# ATSAMA5D31 register map
Vendor: Atmel; Series: SAMA5D3; File version: 20130221
Registers are 32-bit, read-write, reset 0x0 unless marked. A register's access mark holds for its fields unless they carry their own. Offsets are from the block's base; [hi:lo] are bit positions; {n}, {i} and the like mark numbered series; 'fields as' and 'values as' point back to an identical list.

## LCDC — LCD Controller
Base 0xF0030000; register names take the prefix LCDC_
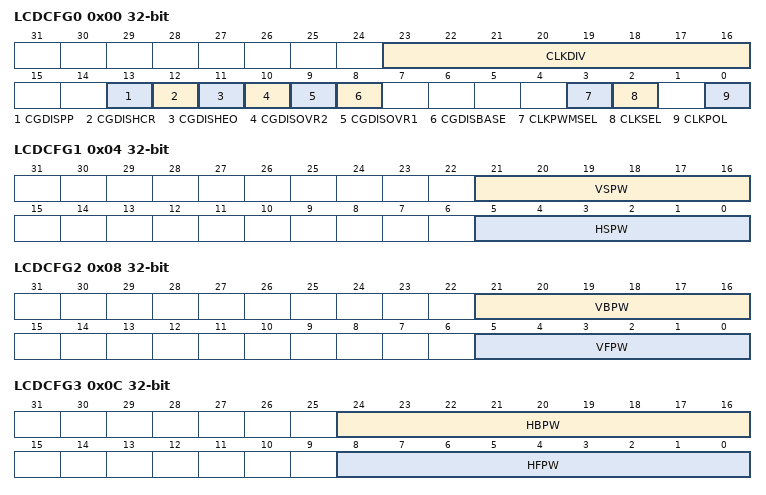
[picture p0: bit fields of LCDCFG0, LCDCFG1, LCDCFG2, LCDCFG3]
0x00 LCDCFG0 — LCD Controller Configuration Register 0
  [23:16] CLKDIV — LCD Controller Clock Divider
  [13] CGDISPP — Clock Gating Disable Control for the Post Processing Layer
  [12] CGDISHCR — Clock Gating Disable Control for the Hardware Cursor Layer
  [11] CGDISHEO — Clock Gating Disable Control for the High End Overlay
  [10] CGDISOVR2 — Clock Gating Disable Control for the Overlay 2 Layer
  [9] CGDISOVR1 — Clock Gating Disable Control for the Overlay 1 Layer
  [8] CGDISBASE — Clock Gating Disable Control for the Base Layer
  [3] CLKPWMSEL — LCD Controller PWM Clock Source Selection
  [2] CLKSEL — LCD Controller Clock Source Selection
  [0] CLKPOL — LCD Controller Clock Polarity
0x04 LCDCFG1 — LCD Controller Configuration Register 1
  [21:16] VSPW — Vertical Synchronization Pulse Width
  [5:0] HSPW — Horizontal Synchronization Pulse Width
0x08 LCDCFG2 — LCD Controller Configuration Register 2
  [21:16] VBPW — Vertical Back Porch Width
  [5:0] VFPW — Vertical Front Porch Width
0x0C LCDCFG3 — LCD Controller Configuration Register 3
  [24:16] HBPW — Horizontal Back Porch Width
  [8:0] HFPW — Horizontal Front Porch Width
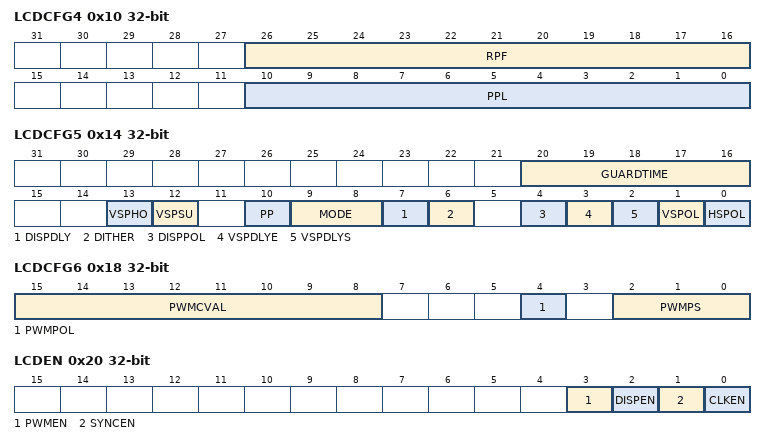
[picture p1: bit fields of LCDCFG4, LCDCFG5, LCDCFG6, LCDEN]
0x10 LCDCFG4 — LCD Controller Configuration Register 4
  [26:16] RPF — Number of Active Row Per Frame
  [10:0] PPL — Number of Pixels Per Line
0x14 LCDCFG5 — LCD Controller Configuration Register 5
  [20:16] GUARDTIME — LCD DISPLAY Guard Time
  [13] VSPHO — LCD Controller Vertical synchronization Pulse Hold Configuration
  [12] VSPSU — LCD Controller Vertical synchronization Pulse Setup Configuration
  [10] PP — Post Processing Enable
  [9:8] MODE — LCD Controller Output Mode
    0=OUTPUT_12BPP (LCD output mode is set to 12 bits per pixel); 1=OUTPUT_16BPP (LCD output mode is set to 16 bits per pixel); 2=OUTPUT_18BPP (LCD output mode is set to 18 bits per pixel); 3=OUTPUT_24BPP (LCD output mode is set to 24 bits per pixel)
  [7] DISPDLY — LCD Controller Display Power Signal Synchronization
  [6] DITHER — LCD Controller Dithering
  [4] DISPPOL — Display Signal Polarity
  [3] VSPDLYE — Vertical Synchronization Pulse End
  [2] VSPDLYS — Vertical Synchronization Pulse Start
  [1] VSPOL — Vertical Synchronization Pulse Polarity
  [0] HSPOL — Horizontal Synchronization Pulse Polarity
0x18 LCDCFG6 — LCD Controller Configuration Register 6
  [15:8] PWMCVAL — LCD Controller PWM Compare Value
  [4] PWMPOL — LCD Controller PWM Signal Polarity
  [2:0] PWMPS — PWM Clock Prescaler
0x20 LCDEN wo reset not defined — LCD Controller Enable Register
  [3] PWMEN — LCD Controller Pulse Width Modulation Enable
  [2] DISPEN — LCD Controller DISP Signal Enable
  [1] SYNCEN — LCD Controller Horizontal and Vertical Synchronization Enable
  [0] CLKEN — LCD Controller Pixel Clock Enable
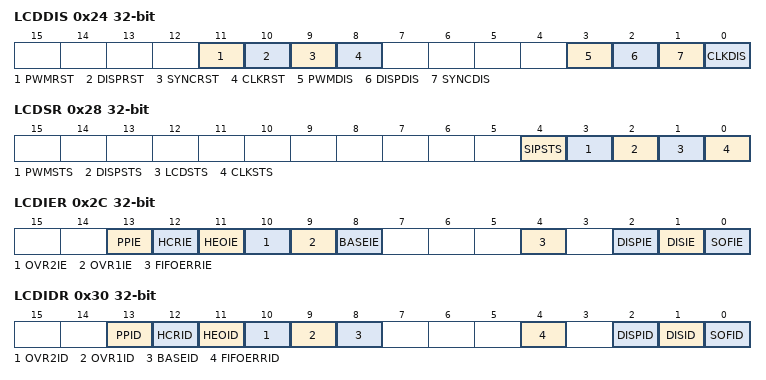
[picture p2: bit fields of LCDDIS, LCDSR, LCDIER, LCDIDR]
0x24 LCDDIS wo reset not defined — LCD Controller Disable Register
  [11] PWMRST — LCD Controller PWM Reset
  [10] DISPRST — LCD Controller DISP Signal Reset
  [9] SYNCRST — LCD Controller Horizontal and Vertical Synchronization Reset
  [8] CLKRST — LCD Controller Clock Reset
  [3] PWMDIS — LCD Controller Pulse Width Modulation Disable
  [2] DISPDIS — LCD Controller DISP Signal Disable
  [1] SYNCDIS — LCD Controller Horizontal and Vertical Synchronization Disable
  [0] CLKDIS — LCD Controller Pixel Clock Disable
0x28 LCDSR ro — LCD Controller Status Register
  [4] SIPSTS — Synchronization In Progress
  [3] PWMSTS — LCD Controller PWM Signal Status
  [2] DISPSTS — LCD Controller DISP Signal Status
  [1] LCDSTS — LCD Controller Synchronization status
  [0] CLKSTS — Clock Status
0x2C LCDIER wo reset not defined — LCD Controller Interrupt Enable Register
  [13] PPIE — Post Processing Interrupt Enable Register
  [12] HCRIE — Hardware Cursor Interrupt Enable Register
  [11] HEOIE — High End Overlay Interrupt Enable Register
  [10] OVR2IE — Overlay 2 Interrupt Enable Register
  [9] OVR1IE — Overlay 1 Interrupt Enable Register
  [8] BASEIE — Base Layer Interrupt Enable Register
  [4] FIFOERRIE — Output FIFO Error Interrupt Enable Register
  [2] DISPIE — Power UP/Down Sequence Terminated Interrupt Enable Register
  [1] DISIE — LCD Disable Interrupt Enable Register
  [0] SOFIE — Start of Frame Interrupt Enable Register
0x30 LCDIDR wo reset not defined — LCD Controller Interrupt Disable Register
  [13] PPID — Post Processing Interrupt Disable Register
  [12] HCRID — Hardware Cursor Interrupt Disable Register
  [11] HEOID — High End Overlay Interrupt Disable Register
  [10] OVR2ID — Overlay 2 Interrupt Disable Register
  [9] OVR1ID — Overlay 1 Interrupt Disable Register
  [8] BASEID — Base Layer Interrupt Disable Register
  [4] FIFOERRID — Output FIFO Error Interrupt Disable Register
  [2] DISPID — Power UP/Down Sequence Terminated Interrupt Disable Register
  [1] DISID — LCD Disable Interrupt Disable Register
  [0] SOFID — Start of Frame Interrupt Disable Register
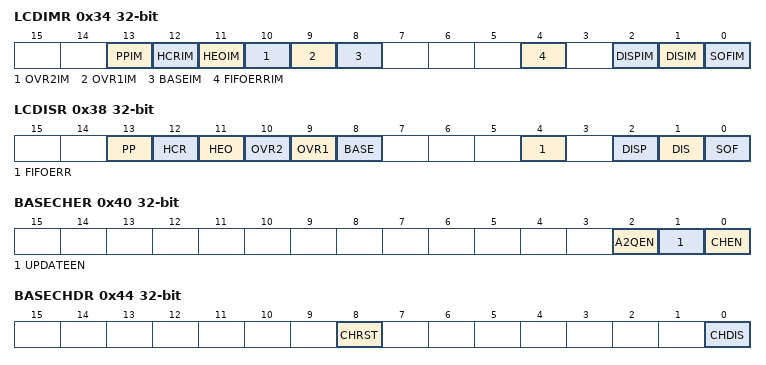
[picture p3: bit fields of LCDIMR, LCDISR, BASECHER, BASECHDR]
0x34 LCDIMR ro — LCD Controller Interrupt Mask Register
  [13] PPIM — Post Processing Interrupt Mask Register
  [12] HCRIM — Hardware Cursor Interrupt Mask Register
  [11] HEOIM — High End Overlay Interrupt Mask Register
  [10] OVR2IM — Overlay 2 Interrupt Mask Register
  [9] OVR1IM — Overlay 1 Interrupt Mask Register
  [8] BASEIM — Base Layer Interrupt Mask Register
  [4] FIFOERRIM — Output FIFO Error Interrupt Mask Register
  [2] DISPIM — Power UP/Down Sequence Terminated Interrupt Mask Register
  [1] DISIM — LCD Disable Interrupt Mask Register
  [0] SOFIM — Start of Frame Interrupt Mask Register
0x38 LCDISR ro — LCD Controller Interrupt Status Register
  [13] PP — Post Processing Raw Interrupt Status Register
  [12] HCR — Hardware Cursor Raw Interrupt Status Register
  [11] HEO — High End Overlay Raw Interrupt Status Register
  [10] OVR2 — Overlay 2 Raw Interrupt Status Register
  [9] OVR1 — Overlay 1 Raw Interrupt Status Register
  [8] BASE — Base Layer Raw Interrupt Status Register
  [4] FIFOERR — Output FIFO Error
  [2] DISP — Power-up/Power-down Sequence Terminated Interrupt Status Register
  [1] DIS — LCD Disable Interrupt Status Register
  [0] SOF — Start of Frame Interrupt Status Register
0x40 BASECHER wo — Base Layer Channel Enable Register
  [2] A2QEN — Add Head Pointer Enable Register
  [1] UPDATEEN — Update Overlay Attributes Enable Register
  [0] CHEN — Channel Enable Register
0x44 BASECHDR wo — Base Layer Channel Disable Register
  [8] CHRST — Channel Reset Register
  [0] CHDIS — Channel Disable Register
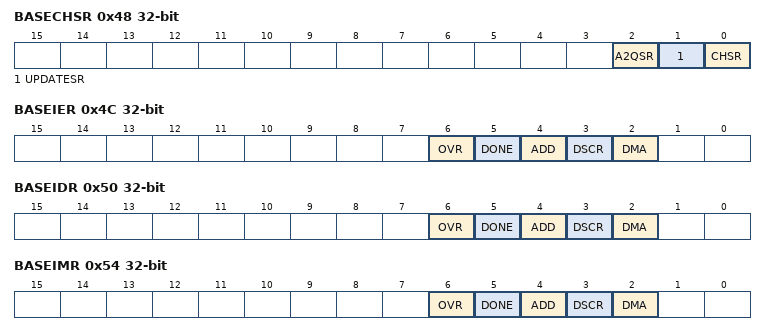
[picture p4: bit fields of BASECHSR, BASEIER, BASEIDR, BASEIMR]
0x48 BASECHSR ro — Base Layer Channel Status Register
  [2] A2QSR — Add To Queue Pending Register
  [1] UPDATESR — Update Overlay Attributes In Progress
  [0] CHSR — Channel Status Register
0x4C BASEIER wo — Base Layer Interrupt Enable Register
  [6] OVR — Overflow Interrupt Enable Register
  [5] DONE — End of List Interrupt Enable Register
  [4] ADD — Head Descriptor Loaded Interrupt Enable Register
  [3] DSCR — Descriptor Loaded Interrupt Enable Register
  [2] DMA — End of DMA Transfer Interrupt Enable Register
0x50 BASEIDR wo — Base Layer Interrupt Disabled Register
  [6] OVR — Overflow Interrupt Disable Register
  [5] DONE — End of List Interrupt Disable Register
  [4] ADD — Head Descriptor Loaded Interrupt Disable Register
  [3] DSCR — Descriptor Loaded Interrupt Disable Register
  [2] DMA — End of DMA Transfer Interrupt Disable Register
0x54 BASEIMR ro — Base Layer Interrupt Mask Register
  [6] OVR — Overflow Interrupt Mask Register
  [5] DONE — End of List Interrupt Mask Register
  [4] ADD — Head Descriptor Loaded Interrupt Mask Register
  [3] DSCR — Descriptor Loaded Interrupt Mask Register
  [2] DMA — End of DMA Transfer Interrupt Mask Register
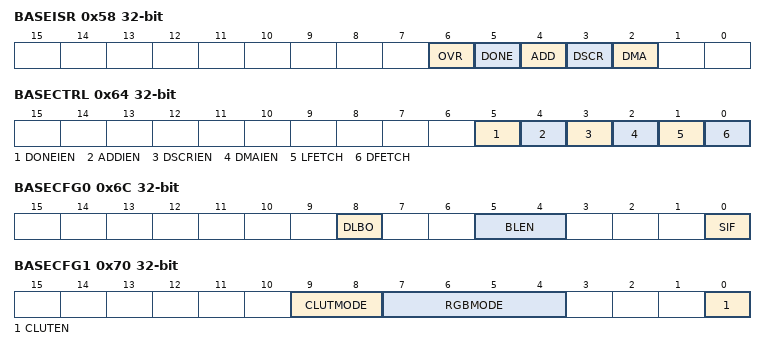
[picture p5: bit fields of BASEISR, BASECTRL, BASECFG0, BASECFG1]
0x58 BASEISR ro — Base Layer Interrupt status Register
  [6] OVR — Overflow Detected
  [5] DONE — End of List Detected
  [4] ADD — Head Descriptor Loaded
  [3] DSCR — DMA Descriptor Loaded
  [2] DMA — End of DMA Transfer
0x5C BASEHEAD — Base DMA Head Register
  [31:2] HEAD — DMA Head Pointer
0x60 BASEADDR — Base DMA Address Register
  [31:0] ADDR — DMA Transfer Start Address
0x64 BASECTRL — Base DMA Control Register
  [5] DONEIEN — End of List Interrupt Enable
  [4] ADDIEN — Add Head Descriptor to Queue Interrupt Enable
  [3] DSCRIEN — Descriptor Loaded Interrupt Enable
  [2] DMAIEN — End of DMA Transfer Interrupt Enable
  [1] LFETCH — Lookup Table Fetch Enable
  [0] DFETCH — Transfer Descriptor Fetch Enable
0x68 BASENEXT — Base DMA Next Register
  [31:0] NEXT — DMA Descriptor Next Address
0x6C BASECFG0 — Base Configuration register 0
  [8] DLBO — Defined Length Burst Only For Channel Bus Transaction.
  [5:4] BLEN — AHB Burst Length
    0=AHB_SINGLE (AHB Access is started as soon as there is enough space in the FIFO to store one data. SINGLE, INCR, INCR4, INCR8 and INCR16 bursts are used. INCR is used for a burst of 2 and 3 beats.); 1=AHB_INCR4 (AHB Access is started as soon as there is enough space in the FIFO to store a total amount of 4 data. An AHB INCR4 Burst is used. SINGLE, INCR and INCR4 bursts are used. INCR is used for a burst of 2 and 3 beats.); 2=AHB_INCR8 (AHB Access is started as soon as there is enough space in the FIFO to store a total amount of 8 data. An AHB INCR8 Burst is used. SINGLE, INCR, INCR4 and INCR8 bursts are used. INCR is used for a burst of 2 and 3 beats.); 3=AHB_INCR16 (AHB Access is started as soon as there is enough space in the FIFO to store a total amount of 16 data. An AHB INCR16 Burst is used. SINGLE, INCR, INCR4, INCR8 and INCR16 bursts are used. INCR is used for a burst of 2 and 3 beats.)
  [0] SIF — Source Interface
0x70 BASECFG1 — Base Configuration register 1
  [9:8] CLUTMODE — Color Lookup Table Input Mode Selection
    0=CLUT_1BPP (color lookup table mode set to 1 bit per pixel); 1=CLUT_2BPP (color lookup table mode set to 2 bits per pixel); 2=CLUT_4BPP (color lookup table mode set to 4 bits per pixel); 3=CLUT_8BPP (color lookup table mode set to 8 bits per pixel)
  [7:4] RGBMODE — RGB Input Mode Selection
    0=12BPP_RGB_444; 1=16BPP_ARGB_4444; 2=16BPP_RGBA_4444; 3=16BPP_RGB_565; 4=16BPP_TRGB_1555; 5=18BPP_RGB_666; 6=18BPP_RGB_666PACKED; 7=19BPP_TRGB_1666; 8=19BPP_TRGB_PACKED (19 bpp TRGB 1666 PACKED); 9=24BPP_RGB_888; 10=24BPP_RGB_888_PACKED; 11=25BPP_TRGB_1888; 12=32BPP_ARGB_8888; 13=32BPP_RGBA_8888
  [0] CLUTEN — Color Lookup Table Enable
0x74 BASECFG2 — Base Configuration register 2
  [31:0] XSTRIDE — Horizontal Stride
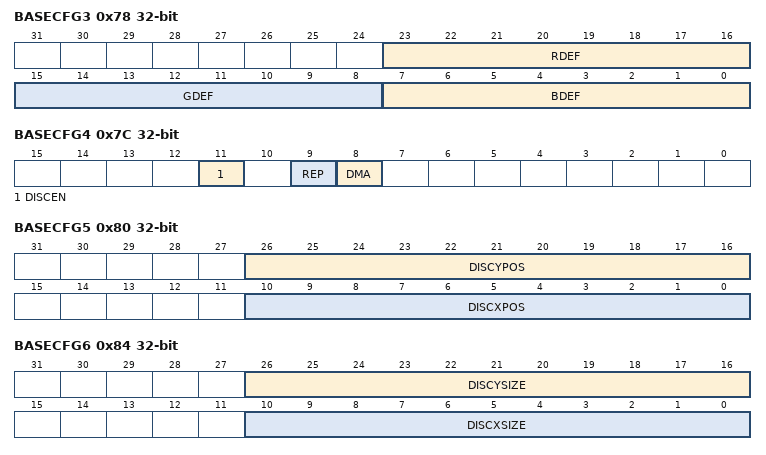
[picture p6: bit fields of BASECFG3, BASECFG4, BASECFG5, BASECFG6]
0x78 BASECFG3 — Base Configuration register 3
  [23:16] RDEF — Red Default
  [15:8] GDEF — Green Default
  [7:0] BDEF — Blue Default
0x7C BASECFG4 — Base Configuration register 4
  [11] DISCEN — Discard Area Enable
  [9] REP — Use Replication logic to expand RGB color to 24 bits
  [8] DMA — Use DMA Data Path
0x80 BASECFG5 — Base Configuration register 5
  [26:16] DISCYPOS — Discard Area Vertical coordinate
  [10:0] DISCXPOS — Discard Area horizontal coordinate
0x84 BASECFG6 — Base Configuration register 6
  [26:16] DISCYSIZE — Discard Area Vertical Size
  [10:0] DISCXSIZE — Discard Area Horizontal Size
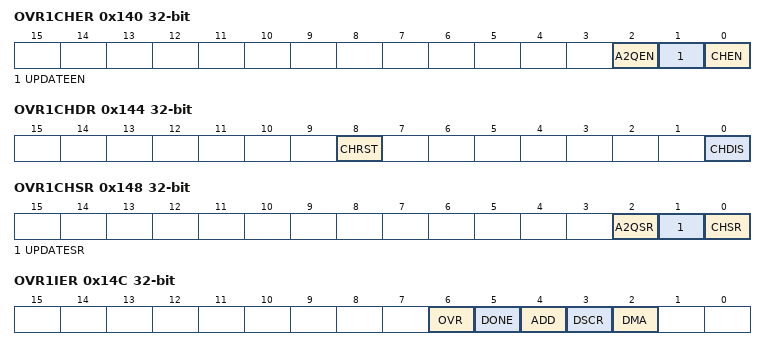
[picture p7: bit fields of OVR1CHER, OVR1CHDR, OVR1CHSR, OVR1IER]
0x140 OVR1CHER wo — Overlay 1 Channel Enable Register
  fields as BASECHER
0x144 OVR1CHDR wo — Overlay 1 Channel Disable Register
  fields as BASECHDR
0x148 OVR1CHSR ro — Overlay 1 Channel Status Register
  [2] A2QSR — Add to Queue Pending Register
  [1] UPDATESR — Update Overlay Attributes In Progress
  [0] CHSR — Channel Status Register
0x14C OVR1IER wo — Overlay 1 Interrupt Enable Register
  fields as BASEIER
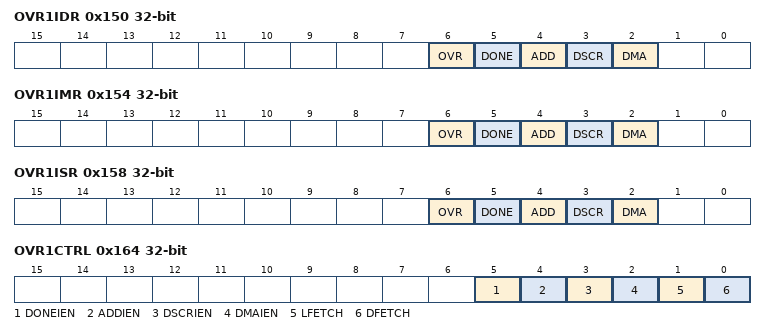
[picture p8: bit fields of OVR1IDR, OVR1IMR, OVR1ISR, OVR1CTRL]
0x150 OVR1IDR wo — Overlay 1 Interrupt Disable Register
  fields as BASEIDR
0x154 OVR1IMR ro — Overlay 1 Interrupt Mask Register
  fields as BASEIMR
0x158 OVR1ISR ro — Overlay 1 Interrupt Status Register
  [6] OVR — Overflow Detected
  [5] DONE — End of List Detected Register
  [4] ADD — Head Descriptor Loaded
  [3] DSCR — DMA Descriptor Loaded
  [2] DMA — End of DMA Transfer
0x15C OVR1HEAD — Overlay 1 DMA Head Register
  [31:2] HEAD — DMA Head Pointer
0x160 OVR1ADDR — Overlay 1 DMA Address Register
  [31:0] ADDR — DMA Transfer Overlay 1 Address
0x164 OVR1CTRL — Overlay1 DMA Control Register
  fields as BASECTRL
0x168 OVR1NEXT — Overlay1 DMA Next Register
  [31:0] NEXT — DMA Descriptor Next Address
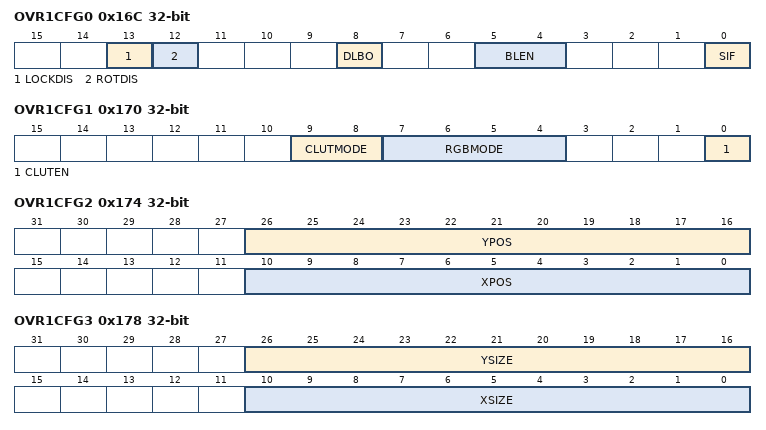
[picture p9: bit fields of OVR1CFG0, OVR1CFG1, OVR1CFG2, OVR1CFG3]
0x16C OVR1CFG0 — Overlay 1 Configuration 0 Register
  [13] LOCKDIS — Hardware Rotation Lock Disable
  [12] ROTDIS — Hardware Rotation Optimization Disable
  [8] DLBO — Defined Length Burst Only for Channel Bus Transaction.
  [5:4] BLEN — AHB Burst Length
    0=AHB_BLEN_SINGLE (AHB Access is started as soon as there is enough space in the FIFO to store one data. SINGLE, INCR, INCR4, INCR8 and INCR16 bursts are used. INCR is used for a burst of 2 and 3 beats.); 1=AHB_BLEN_INCR4 (AHB Access is started as soon as there is enough space in the FIFO to store a total amount of 4 data. An AHB INCR4 Burst is used. SINGLE, INCR and INCR4 bursts are used. INCR is used for a burst of 2 and 3 beats.); 2=AHB_BLEN_INCR8 (AHB Access is started as soon as there is enough space in the FIFO to store a total amount of 8 data. An AHB INCR8 Burst is used. SINGLE, INCR, INCR4 and INCR8 bursts are used. INCR is used for a burst of 2 and 3 beats.); 3=AHB_BLEN_INCR16 (AHB Access is started as soon as there is enough space in the FIFO to store a total amount of 16 data. An AHB INCR16 Burst is used. SINGLE, INCR, INCR4, INCR8 and INCR16 bursts are used. INCR is used for a burst of 2 and 3 beats.)
  [0] SIF — Source Interface
0x170 OVR1CFG1 — Overlay 1 Configuration 1 Register
  [9:8] CLUTMODE — Color Lookup table input mode selection
    values as BASECFG1.CLUTMODE
  [7:4] RGBMODE — RGB Input Mode Selection
    values as BASECFG1.RGBMODE
  [0] CLUTEN — Color Lookup Table Enable
0x174 OVR1CFG2 — Overlay 1 Configuration 2 Register
  [26:16] YPOS — Vertical Window Position
  [10:0] XPOS — Horizontal Window Position
0x178 OVR1CFG3 — Overlay 1 Configuration 3 Register
  [26:16] YSIZE — Vertical Window Size
  [10:0] XSIZE — Horizontal Window Size
0x17C OVR1CFG4 — Overlay 1 Configuration 4 Register
  [31:0] XSTRIDE — Horizontal Stride
0x180 OVR1CFG5 — Overlay 1 Configuration 5 Register
  [31:0] PSTRIDE — Pixel Stride
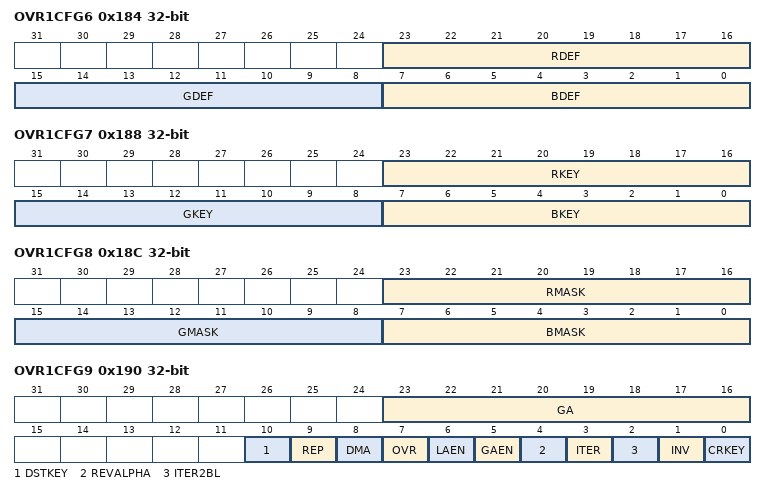
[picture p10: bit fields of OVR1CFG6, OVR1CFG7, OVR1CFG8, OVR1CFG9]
0x184 OVR1CFG6 — Overlay 1 Configuration 6 Register
  fields as BASECFG3
0x188 OVR1CFG7 — Overlay 1 Configuration 7 Register
  [23:16] RKEY — Red Color Component Chroma Key
  [15:8] GKEY — Green Color Component Chroma Key
  [7:0] BKEY — Blue Color Component Chroma Key
0x18C OVR1CFG8 — Overlay 1 Configuration 8Register
  [23:16] RMASK — Red Color Component Chroma Key Mask
  [15:8] GMASK — Green Color Component Chroma Key Mask
  [7:0] BMASK — Blue Color Component Chroma Key Mask
0x190 OVR1CFG9 — Overlay 1 Configuration 9 Register
  [23:16] GA — Blender Global Alpha
  [10] DSTKEY — Destination Chroma Keying
  [9] REP — Use Replication logic to expand RGB color to 24 bits
  [8] DMA — Blender DMA Layer Enable
  [7] OVR — Blender Overlay Layer Enable
  [6] LAEN — Blender Local Alpha Enable
  [5] GAEN — Blender Global Alpha Enable
  [4] REVALPHA — Blender Reverse Alpha
  [3] ITER — Blender Use Iterated Color
  [2] ITER2BL — Blender Iterated Color Enable
  [1] INV — Blender Inverted Blender Output Enable
  [0] CRKEY — Blender Chroma Key Enable
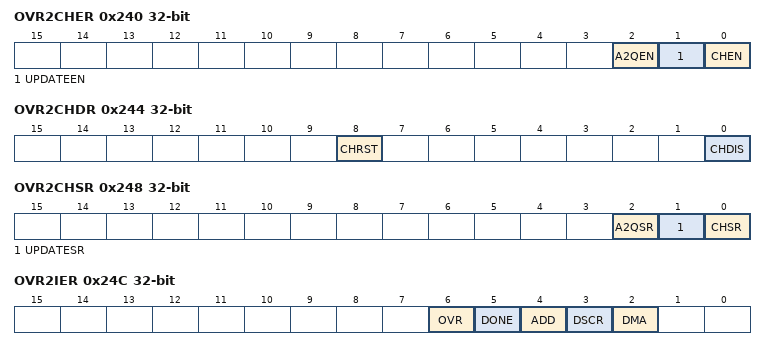
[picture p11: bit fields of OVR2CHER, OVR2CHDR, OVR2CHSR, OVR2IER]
0x240 OVR2CHER wo — Overlay 2 Channel Enable Register
  fields as BASECHER
0x244 OVR2CHDR wo — Overlay 2 Channel Disable Register
  fields as BASECHDR
0x248 OVR2CHSR ro — Overlay 2 Channel Status Register
  fields as BASECHSR
0x24C OVR2IER wo — Overlay 2 Interrupt Enable Register
  fields as BASEIER
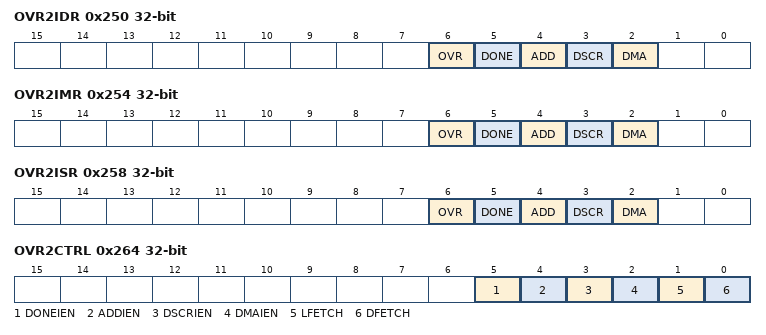
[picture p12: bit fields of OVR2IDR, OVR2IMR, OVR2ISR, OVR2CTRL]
0x250 OVR2IDR wo — Overlay 2 Interrupt Disable Register
  fields as BASEIDR
0x254 OVR2IMR ro — Overlay 2 Interrupt Mask Register
  fields as BASEIMR
0x258 OVR2ISR ro — Overlay 2 Interrupt status Register
  [6] OVR — Overflow Detected
  [5] DONE — End Of List Interrupt Disable Register
  [4] ADD — Head Descriptor Loaded Interrupt Disable Register
  [3] DSCR — DMA Descriptor Loaded
  [2] DMA — End of DMA Transfer
0x25C OVR2HEAD — Overlay 2 DMA Head Register
  [31:2] HEAD — DMA Head Pointer
0x260 OVR2ADDR — Overlay 2 DMA Address Register
  [31:0] ADDR — DMA Transfer Overlay 2 Address
0x264 OVR2CTRL — Overlay 2 DMA Control Register
  fields as BASECTRL
0x268 OVR2NEXT — Overlay 2 DMA Next Register
  [31:0] NEXT — DMA Descriptor Next Address
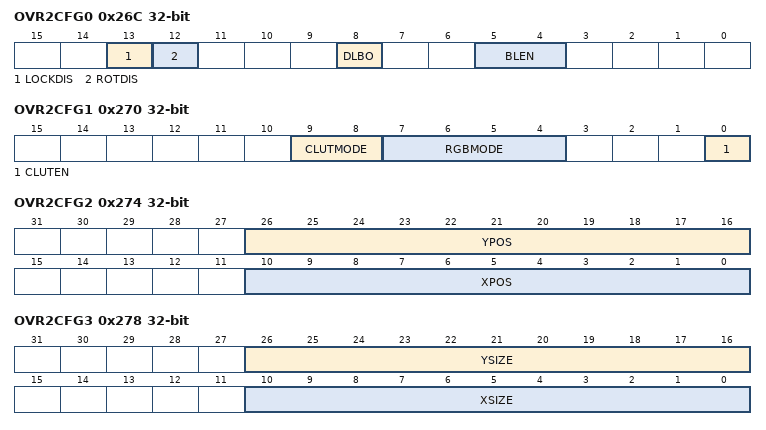
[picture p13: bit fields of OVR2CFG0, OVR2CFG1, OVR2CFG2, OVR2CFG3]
0x26C OVR2CFG0 — Overlay 2 Configuration 0 Register
  [13] LOCKDIS — Hardware Rotation Lock Disable
  [12] ROTDIS — Hardware Rotation Optimization Disable
  [8] DLBO — Defined Length Burst Only For Channel Bus Transaction.
  [5:4] BLEN — AHB Burst Length
    values as BASECFG0.BLEN
0x270 OVR2CFG1 — Overlay 2 Configuration 1 Register
  fields as OVR1CFG1
0x274 OVR2CFG2 — Overlay 2 Configuration 2 Register
  fields as OVR1CFG2
0x278 OVR2CFG3 — Overlay 2 Configuration 3 Register
  fields as OVR1CFG3
0x27C OVR2CFG4 — Overlay 2 Configuration 4 Register
  [31:0] XSTRIDE — Horizontal Stride
0x280 OVR2CFG5 — Overlay 2 Configuration 5 Register
  [31:0] PSTRIDE — Pixel Stride
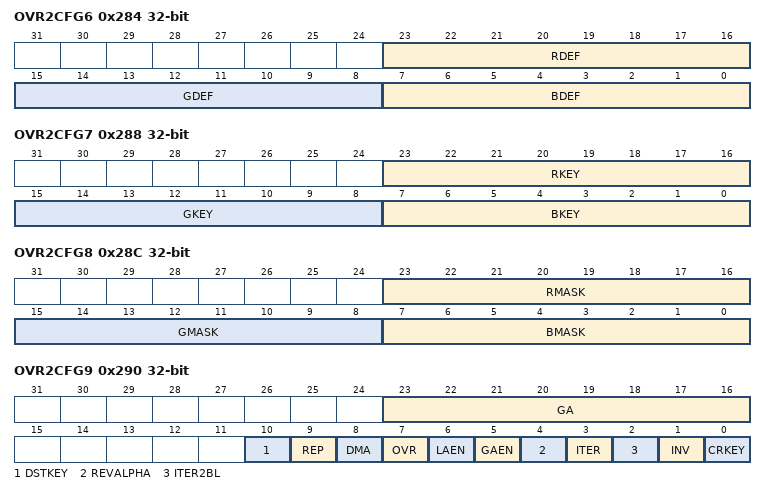
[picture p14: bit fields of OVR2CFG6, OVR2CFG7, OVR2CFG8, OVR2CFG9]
0x284 OVR2CFG6 — Overlay 2 Configuration 6 Register
  fields as BASECFG3
0x288 OVR2CFG7 — Overlay 2 Configuration 7 Register
  fields as OVR1CFG7
0x28C OVR2CFG8 — Overlay 2 Configuration 8 Register
  fields as OVR1CFG8
0x290 OVR2CFG9 — Overlay 2 Configuration 9 Register
  fields as OVR1CFG9
0x340 HEOCHER wo — High-End Overlay Channel Enable Register
  fields as BASECHER
0x344 HEOCHDR wo — High-End Overlay Channel Disable Register
  fields as BASECHDR
0x348 HEOCHSR ro — High-End Overlay Channel Status Register
  fields as BASECHSR
0x34C HEOIER wo — High-End Overlay Interrupt Enable Register
  [22] VOVR — Overflow for V Chrominance Interrupt Enable Register
  [21] VDONE — End of List for V Chrominance Interrupt Enable Register
  [20] VADD — Head Descriptor Loaded for V Chrominance Interrupt Enable Register
  [19] VDSCR — Descriptor Loaded for V Chrominance Interrupt Enable Register
  [18] VDMA — End of DMA for V Chrominance Transfer Interrupt Enable Register
  [14] UOVR — Overflow for U or UV Chrominance Interrupt Enable Register
  [13] UDONE — End of List for U or UV Chrominance Interrupt Enable Register
  [12] UADD — Head Descriptor Loaded for U or UV Chrominance Interrupt Enable Register
  [11] UDSCR — Descriptor Loaded for U or UV Chrominance Interrupt Enable Register
  [10] UDMA — End of DMA Transfer for U or UV Chrominance Interrupt Enable Register
  [6] OVR — Overflow Interrupt Enable Register
  [5] DONE — End of List Interrupt Enable Register
  [4] ADD — Head Descriptor Loaded Interrupt Enable Register
  [3] DSCR — Descriptor Loaded Interrupt Enable Register
  [2] DMA — End of DMA Transfer Interrupt Enable Register
0x350 HEOIDR wo — High-End Overlay Interrupt Disable Register
  [22] VOVR — Overflow for V Chrominance Component Interrupt Disable Register
  [21] VDONE — End of List for V Chrominance Component Interrupt Disable Register
  [20] VADD — Head Descriptor Loaded for V Chrominance Component Interrupt Disable Register
  [19] VDSCR — Descriptor Loaded for V Chrominance Component Interrupt Disable Register
  [18] VDMA — End of DMA Transfer for V Chrominance Component Interrupt Disable Register
  [14] UOVR — Overflow Interrupt for U or UV Chrominance Component Disable Register
  [13] UDONE — End of List Interrupt for U or UV Chrominance Component Disable Register
  [12] UADD — Head Descriptor Loaded for U or UV Chrominance Component Interrupt Disable Register
  [11] UDSCR — Descriptor Loaded for U or UV Chrominance Component Interrupt Disable Register
  [10] UDMA — End of DMA Transfer for U or UV Chrominance Component Interrupt Disable Register
  [6] OVR — Overflow Interrupt Disable Register
  [5] DONE — End of List Interrupt Disable Register
  [4] ADD — Head Descriptor Loaded Interrupt Disable Register
  [3] DSCR — Descriptor Loaded Interrupt Disable Register
  [2] DMA — End of DMA Transfer Interrupt Disable Register
0x354 HEOIMR ro — High-End Overlay Interrupt Mask Register
  [22] VOVR — Overflow for V Chrominance Interrupt Mask Register
  [21] VDONE — End of List for V Chrominance Component Mask Register
  [20] VADD — Head Descriptor Loaded for V Chrominance Component Mask Register
  [19] VDSCR — Descriptor Loaded for V Chrominance Component Interrupt Mask Register
  [18] VDMA — End of DMA Transfer for V Chrominance Component Interrupt Mask Register
  [14] UOVR — Overflow for U Chrominance Interrupt Mask Register
  [13] UDONE — End of List for U or UV Chrominance Component Mask Register
  [12] UADD — Head Descriptor Loaded for U or UV Chrominance Component Mask Register
  [11] UDSCR — Descriptor Loaded for U or UV Chrominance Component Interrupt Mask Register
  [10] UDMA — End of DMA Transfer for U or UV Chrominance Component Interrupt Mask Register
  [6] OVR — Overflow Interrupt Mask Register
  [5] DONE — End of List Interrupt Mask Register
  [4] ADD — Head Descriptor Loaded Interrupt Mask Register
  [3] DSCR — Descriptor Loaded Interrupt Mask Register
  [2] DMA — End of DMA Transfer Interrupt Mask Register
0x358 HEOISR ro — High-End Overlay Interrupt Status Register
  [22] VOVR — Overflow Detected for V component
  [21] VDONE — End of List Detected for V component
  [20] VADD — Head Descriptor Loaded for V component
  [19] VDSCR — DMA Descriptor Loaded for V component
  [18] VDMA — End of DMA Transfer for V component
  [14] UOVR — Overflow Detected for U component
  [13] UDONE — End of List Detected for U component
  [12] UADD — Head Descriptor Loaded for U component
  [11] UDSCR — DMA Descriptor Loaded for U component
  [10] UDMA — End of DMA Transfer for U component
  [6] OVR — Overflow Detected
  [5] DONE — End of List Detected
  [4] ADD — Head Descriptor Loaded
  [3] DSCR — DMA Descriptor Loaded
  [2] DMA — End of DMA Transfer
0x35C HEOHEAD — High-End Overlay DMA Head Register
  [31:2] HEAD — DMA Head Pointer
0x360 HEOADDR — High-End Overlay DMA Address Register
  [31:0] ADDR — DMA Transfer start Address
0x364 HEOCTRL — High-End Overlay DMA Control Register
  fields as BASECTRL
0x368 HEONEXT — High-End Overlay DMA Next Register
  [31:0] NEXT — DMA Descriptor Next Address
0x36C HEOUHEAD — High-End Overlay U DMA Head Register
  [31:0] UHEAD — DMA Head Pointer
0x370 HEOUADDR — High-End Overlay U DMA Address Register
  [31:0] UADDR — DMA Transfer Start Address for U or UV Chrominance
0x374 HEOUCTRL — High-End Overlay U DMA control Register
  [5] UDONEIEN — End of List Interrupt Enable
  [4] UADDIEN — Add Head Descriptor to Queue Interrupt Enable
  [3] UDSCRIEN — Descriptor Loaded Interrupt Enable
  [2] UDMAIEN — End of DMA Transfer Interrupt Enable
  [0] UDFETCH — Transfer Descriptor Fetch Enable
0x378 HEOUNEXT — High-End Overlay U DMA Next Register
  [31:0] UNEXT — DMA Descriptor Next Address
0x37C HEOVHEAD — High-End Overlay V DMA Head Register
  [31:0] VHEAD — DMA Head Pointer
0x380 HEOVADDR — High-End Overlay V DMA Address Register
  [31:0] VADDR — DMA Transfer Start Address for V Chrominance
0x384 HEOVCTRL — High-End Overlay V DMA control Register
  [5] VDONEIEN — End of List Interrupt Enable
  [4] VADDIEN — Add Head Descriptor to Queue Interrupt Enable
  [3] VDSCRIEN — Descriptor Loaded Interrupt Enable
  [2] VDMAIEN — End of DMA Transfer Interrupt Enable
  [0] VDFETCH — Transfer Descriptor Fetch Enable
0x388 HEOVNEXT — High-End Overlay VDMA Next Register
  [31:0] VNEXT — DMA Descriptor Next Address
0x38C HEOCFG0 — High-End Overlay Configuration Register 0
  [13] LOCKDIS — Hardware Rotation Lock Disable
  [12] ROTDIS — Hardware Rotation Optimization Disable
  [8] DLBO — Defined Length Burst Only For Channel Bus Transaction.
  [7:6] BLENUV — AHB Burst Length for U-V channel
    values as BASECFG0.BLEN
  [5:4] BLEN — AHB Burst Length
    values as OVR1CFG0.BLEN
  [0] SIF — Source Interface
0x390 HEOCFG1 — High-End Overlay Configuration Register 1
  [20] DSCALEOPT — Down Scaling Bandwidth Optimization
  [17] YUV422SWP — YUV 4:2:2 SWAP
  [16] YUV422ROT — YUV 4:2:2 Rotation
  [15:12] YUVMODE — YUV input mode selection
    0=32BPP_AYCBCR (32 bpp AYCbCr 444); 1=16BPP_YCBCR_MODE0 (16 bpp Cr(n)Y(n+1)Cb(n)Y(n) 422); 2=16BPP_YCBCR_MODE1 (16 bpp Y(n+1)Cr(n)Y(n)Cb(n) 422); 3=16BPP_YCBCR_MODE2 (16 bpp Cb(n)Y(+1)Cr(n)Y(n) 422); 4=16BPP_YCBCR_MODE3 (16 bpp Y(n+1)Cb(n)Y(n)Cr(n) 422); 5=16BPP_YCBCR_SEMIPLANAR (16 bpp Semiplanar 422 YCbCr); 6=16BPP_YCBCR_PLANAR (16 bpp Planar 422 YCbCr); 7=12BPP_YCBCR_SEMIPLANAR (12 bpp Semiplanar 420 YCbCr); 8=12BPP_YCBCR_PLANAR (12 bpp Planar 420 YCbCr)
  [9:8] CLUTMODE — Color Lookup table input mode selection
    values as BASECFG1.CLUTMODE
  [7:4] RGBMODE — RGB input mode selection
    values as BASECFG1.RGBMODE
  [1] YUVEN — YUV Color Space Enable
  [0] CLUTEN — Color Lookup Table Enable
0x394 HEOCFG2 — High-End Overlay Configuration Register 2
  fields as OVR1CFG2
0x398 HEOCFG3 — High-End Overlay Configuration Register 3
  fields as OVR1CFG3
0x39C HEOCFG4 — High-End Overlay Configuration Register 4
  [26:16] YMEMSIZE — Vertical image Size in Memory
  [10:0] XMEMSIZE — Horizontal image Size in Memory
0x3A0 HEOCFG5 — High-End Overlay Configuration Register 5
  [31:0] XSTRIDE — Horizontal Stride
0x3A4 HEOCFG6 — High-End Overlay Configuration Register 6
  [31:0] PSTRIDE — Pixel Stride
0x3A8 HEOCFG7 — High-End Overlay Configuration Register 7
  [31:0] UVXSTRIDE — UV Horizontal Stride
0x3AC HEOCFG8 — High-End Overlay Configuration Register 8
  [31:0] UVPSTRIDE — UV Pixel Stride
0x3B0 HEOCFG9 — High-End Overlay Configuration Register 9
  fields as BASECFG3
0x3B4 HEOCFG10 — High-End Overlay Configuration Register 10
  fields as OVR1CFG7
0x3B8 HEOCFG11 — High-End Overlay Configuration Register 11
  fields as OVR1CFG8
0x3BC HEOCFG12 — High-End Overlay Configuration Register 12
  [23:16] GA — Blender Global Alpha
  [12] VIDPRI — Video Priority
  [10] DSTKEY — Destination Chroma Keying
  [9] REP — Use Replication logic to expand RGB color to 24 bits
  [8] DMA — Blender DMA Layer Enable
  [7] OVR — Blender Overlay Layer Enable
  [6] LAEN — Blender Local Alpha Enable
  [5] GAEN — Blender Global Alpha Enable
  [4] REVALPHA — Blender Reverse Alpha
  [3] ITER — Blender Use Iterated Color
  [2] ITER2BL — Blender Iterated Color Enable
  [1] INV — Blender Inverted Blender Output Enable
  [0] CRKEY — Blender Chroma Key Enable
0x3C0 HEOCFG13 — High-End Overlay Configuration Register 13
  [31] SCALEN — Hardware Scaler Enable
  [29:16] YFACTOR — Vertical Scaling Factor
  [13:0] XFACTOR — Horizontal Scaling Factor
0x3C4 HEOCFG14 — High-End Overlay Configuration Register 14
  [30] CSCYOFF — Color Space Conversion Offset
  [29:20] CSCRV — Color Space Conversion V coefficient for Red Component 1:2:7 format
  [19:10] CSCRU — Color Space Conversion U coefficient for Red Component 1:2:7 format
  [9:0] CSCRY — Color Space Conversion Y coefficient for Red Component 1:2:7 format
0x3C8 HEOCFG15 — High-End Overlay Configuration Register 15
  [30] CSCUOFF — Color Space Conversion Offset
  [29:20] CSCGV — Color Space Conversion V coefficient for Green Component 1:2:7 format
  [19:10] CSCGU — Color Space Conversion U coefficient for Green Component 1:2:7 format
  [9:0] CSCGY — Color Space Conversion Y coefficient for Green Component 1:2:7 format
0x3CC HEOCFG16 — High-End Overlay Configuration Register 16
  [30] CSCVOFF — Color Space Conversion Offset
  [29:20] CSCBV — Color Space Conversion V coefficient for Blue Component 1:2:7 format
  [19:10] CSCBU — Color Space Conversion U coefficient for Blue Component 1:2:7 format
  [9:0] CSCBY — Color Space Conversion Y coefficient for Blue Component 1:2:7 format
0x3D0 HEOCFG17 — High-End Overlay Configuration Register 17
  [8n+7:8n] XPHI0COEFF{n} (n=0..3) — Horizontal Coefficient for phase 0 tap {n}
0x3D4 HEOCFG18 — High-End Overlay Configuration Register 18
  [7:0] XPHI0COEFF4 — Horizontal Coefficient for phase 0 tap 4
0x3D8 HEOCFG19 — High-End Overlay Configuration Register 19
  [8n+7:8n] XPHI1COEFF{n} (n=0..3) — Horizontal Coefficient for phase 1 tap {n}
0x3DC HEOCFG20 — High-End Overlay Configuration Register 20
  [7:0] XPHI1COEFF4 — Horizontal Coefficient for phase 1 tap 4
0x3E0 HEOCFG21 — High-End Overlay Configuration Register 21
  [8n+7:8n] XPHI2COEFF{n} (n=0..3) — Horizontal Coefficient for phase 2 tap {n}
0x3E4 HEOCFG22 — High-End Overlay Configuration Register 22
  [7:0] XPHI2COEFF4 — Horizontal Coefficient for phase 2 tap 4
0x3E8 HEOCFG23 — High-End Overlay Configuration Register 23
  [8n+7:8n] XPHI3COEFF{n} (n=0..3) — Horizontal Coefficient for phase 3 tap {n}
0x3EC HEOCFG24 — High-End Overlay Configuration Register 24
  [7:0] XPHI3COEFF4 — Horizontal Coefficient for phase 3 tap 4
0x3F0 HEOCFG25 — High-End Overlay Configuration Register 25
  [8n+7:8n] XPHI4COEFF{n} (n=0..3) — Horizontal Coefficient for phase 4 tap {n}
0x3F4 HEOCFG26 — High-End Overlay Configuration Register 26
  [7:0] XPHI4COEFF4 — Horizontal Coefficient for phase 4 tap 4
0x3F8 HEOCFG27 — High-End Overlay Configuration Register 27
  [8n+7:8n] XPHI5COEFF{n} (n=0..3) — Horizontal Coefficient for phase 5 tap {n}
0x3FC HEOCFG28 — High-End Overlay Configuration Register 28
  [7:0] XPHI5COEFF4 — Horizontal Coefficient for phase 5 tap 4
0x400 HEOCFG29 — High-End Overlay Configuration Register 29
  [8n+7:8n] XPHI6COEFF{n} (n=0..3) — Horizontal Coefficient for phase 6 tap {n}
0x404 HEOCFG30 — High-End Overlay Configuration Register 30
  [7:0] XPHI6COEFF4 — Horizontal Coefficient for phase 6 tap 4
0x408 HEOCFG31 — High-End Overlay Configuration Register 31
  [8n+7:8n] XPHI7COEFF{n} (n=0..3) — Horizontal Coefficient for phase 7 tap {n}
0x40C HEOCFG32 — High-End Overlay Configuration Register 32
  [7:0] XPHI7COEFF4 — Horizontal Coefficient for phase 7 tap 4
{0x38C+4i} HEOCFG{i} (i=33..40) — High-End Overlay Configuration Register {i}
  [23:16] YPHI{i-33}COEFF2 — Vertical Coefficient for phase {i-33} tap 2
  [15:8] YPHI{i-33}COEFF1 — Vertical Coefficient for phase {i-33} tap 1
  [7:0] YPHI{i-33}COEFF0 — Vertical Coefficient for phase {i-33} tap 0
0x430 HEOCFG41 — High-End Overlay Configuration Register 41
  [18:16] YPHIDEF — Vertical Filter Phase Offset
  [2:0] XPHIDEF — Horizontal Filter Phase Offset
0x440 HCRCHER wo — Hardware Cursor Channel Enable Register
  fields as BASECHER
0x444 HCRCHDR wo — Hardware Cursor Channel disable Register
  fields as BASECHDR
0x448 HCRCHSR ro — Hardware Cursor Channel Status Register
  fields as BASECHSR
0x44C HCRIER wo — Hardware Cursor Interrupt Enable Register
  fields as BASEIER
0x450 HCRIDR wo — Hardware Cursor Interrupt Disable Register
  fields as BASEIDR
0x454 HCRIMR ro — Hardware Cursor Interrupt Mask Register
  fields as BASEIMR
0x458 HCRISR ro — Hardware Cursor Interrupt Status Register
  fields as BASEISR
0x45C HCRHEAD — Hardware Cursor DMA Head Register
  [31:2] HEAD — DMA Head Pointer
0x460 HCRADDR — Hardware cursor DMA Address Register
  [31:0] ADDR — DMA Transfer start address
0x464 HCRCTRL — Hardware Cursor DMA Control Register
  fields as BASECTRL
0x468 HCRNEXT — Hardware Cursor DMA NExt Register
  [31:0] NEXT — DMA Descriptor Next Address
0x46C HCRCFG0 — Hardware Cursor Configuration 0 Register
  [8] DLBO — Defined Length Burst Only for Channel Bus Transaction.
  [5:4] BLEN — AHB Burst Length
    values as OVR1CFG0.BLEN
  [0] SIF — Source Interface
0x470 HCRCFG1 — Hardware Cursor Configuration 1 Register
  [9:8] CLUTMODE — Color Lookup table input mode selection
    values as BASECFG1.CLUTMODE
  [7:4] RGBMODE — RGB input mode selection
    values as BASECFG1.RGBMODE
  [0] CLUTEN — Color Lookup Table Enable
0x474 HCRCFG2 — Hardware Cursor Configuration 2 Register
  fields as OVR1CFG2
0x478 HCRCFG3 — Hardware Cursor Configuration 3 Register
  fields as OVR1CFG3
0x47C HCRCFG4 — Hardware Cursor Configuration 4 Register
  [31:0] XSTRIDE — Horizontal Stride
0x484 HCRCFG6 — Hardware Cursor Configuration 6 Register
  fields as BASECFG3
0x488 HCRCFG7 — Hardware Cursor Configuration 7 Register
  fields as OVR1CFG7
0x48C HCRCFG8 — Hardware Cursor Configuration 8 Register
  fields as OVR1CFG8
0x490 HCRCFG9 — Hardware Cursor Configuration 9 Register
  fields as OVR1CFG9
0x540 PPCHER wo — Post Processing Channel Enable Register
  fields as BASECHER
0x544 PPCHDR wo — Post Processing Channel Disable Register
  fields as BASECHDR
0x548 PPCHSR ro — Post Processing Channel Status Register
  fields as BASECHSR
0x54C PPIER wo — Post Processing Interrupt Enable Register
  [5] DONE — End of List Interrupt Enable Register
  [4] ADD — Head Descriptor Loaded Interrupt Enable Register
  [3] DSCR — Descriptor Loaded Interrupt Enable Register
  [2] DMA — End of DMA Transfer Interrupt Enable Register
0x550 PPIDR wo — Post Processing Interrupt Disable Register
  [5] DONE — End of List Interrupt Disable Register
  [4] ADD — Head Descriptor Loaded Interrupt Disable Register
  [3] DSCR — Descriptor Loaded Interrupt Disable Register
  [2] DMA — End of DMA Transfer Interrupt Disable Register
0x554 PPIMR ro — Post Processing Interrupt Mask Register
  [5] DONE — End of List Interrupt Mask Register
  [4] ADD — Head Descriptor Loaded Interrupt Mask Register
  [3] DSCR — Descriptor Loaded Interrupt Mask Register
  [2] DMA — End of DMA Transfer Interrupt Mask Register
0x558 PPISR ro — Post Processing Interrupt Status Register
  [5] DONE — End Of List Detected
  [4] ADD — Head Descriptor Loaded
  [3] DSCR — DMA Descriptor Loaded
  [2] DMA — End of DMA Transfer
0x55C PPHEAD — Post Processing Head Register
  [31:2] HEAD — DMA Head Pointer
0x560 PPADDR — Post Processing Address Register
  [31:0] ADDR — DMA Transfer start address
0x564 PPCTRL — Post Processing Control Register
  [5] DONEIEN — End of List Interrupt Enable
  [4] ADDIEN — Add Head Descriptor to Queue Interrupt Enable
  [3] DSCRIEN — Descriptor Loaded Interrupt Enable
  [2] DMAIEN — End of DMA Transfer Interrupt Enable
  [0] DFETCH — Transfer Descriptor Fetch Enable
0x568 PPNEXT — Post Processing Next Register
  [31:0] NEXT — DMA Descriptor Next Address
0x56C PPCFG0 — Post Processing Configuration Register 0
  [8] DLBO — Defined Length Burst Only For Channel Bus Transaction.
  [5:4] BLEN — AHB Burst Length
    values as OVR1CFG0.BLEN
  [0] SIF — Source Interface
0x570 PPCFG1 — Post Processing Configuration Register 1
  [4] ITUBT601 — Color Space Conversion Luminance
  [2:0] PPMODE — Post Processing Output Format selection
    0=PPMODE_RGB_16BPP (RGB 16 bpp); 1=PPMODE_RGB_24BPP_PACKED (RGB 24 bpp PACKED); 2=PPMODE_RGB_24BPP_UNPACKED (RGB 24 bpp UNPACKED); {v}=PPMODE_YCBCR_422_MODE{v-3} (YCbCr 422 16 bpp (Mode {v-3})) (v=3..6)
0x574 PPCFG2 — Post Processing Configuration Register 2
  [31:0] XSTRIDE — Horizontal Stride
0x578 PPCFG3 — Post Processing Configuration Register 3
  [30] CSCYOFF — Color Space Conversion Luminance Offset
  [29:20] CSCYB — Color Space Conversion B coefficient for Luminance component, signed format, step set to 1/1024
  [19:10] CSCYG — Color Space Conversion G coefficient for Luminance component, signed format, step set to 1/512
  [9:0] CSCYR — Color Space Conversion R coefficient for Luminance component, signed format, step set to 1/1024
0x57C PPCFG4 — Post Processing Configuration Register 4
  [30] CSCUOFF — Color Space Conversion Chrominance B Offset
  [29:20] CSCUB — Color Space Conversion B coefficient for Chrominance B component, signed format. (step 1/512)
  [19:10] CSCUG — Color Space Conversion G coefficient for Chrominance B component, signed format. (step 1/512)
  [9:0] CSCUR — Color Space Conversion R coefficient for Chrominance B component, signed format. (step 1/1024)
0x580 PPCFG5 — Post Processing Configuration Register 5
  [30] CSCVOFF — Color Space Conversion Chrominance R Offset
  [29:20] CSCVB — Color Space Conversion B coefficient for Chrominance R component, signed format. (step 1/1024)
  [19:10] CSCVG — Color Space Conversion G coefficient for Chrominance R component, signed format. (step 1/512)
  [9:0] CSCVR — Color Space Conversion R coefficient for Chrominance R component, signed format. (step 1/1024)
{0x600+4i} BASECLUT[{i}] (i=0..255) reset not defined
  [23:16] RCLUT — Red Color entry
  [15:8] GCLUT — Green Color entry
  [7:0] BCLUT — Blue Color entry
{0xA00+4i} OVR1CLUT[{i}] (i=0..255) reset not defined — Overlay 1 CLUT Register
  [31:24] ACLUT — Alpha Color entry
  [23:16] RCLUT — Red Color entry
  [15:8] GCLUT — Green Color entry
  [7:0] BCLUT — Blue Color entry
{0xE00+4i} OVR2CLUT[{i}] (i=0..255) reset not defined — Overlay 2 CLUT Register
  fields as OVR1CLUT[0]
{0x1200+4i} HEOCLUT[{i}] (i=0..255) reset not defined — High End Overlay CLUT Register
  fields as OVR1CLUT[0]
{0x1600+4i} HCRCLUT[{i}] (i=0..255) reset not defined — Hardware Cursor CLUT Register
  fields as OVR1CLUT[0]
